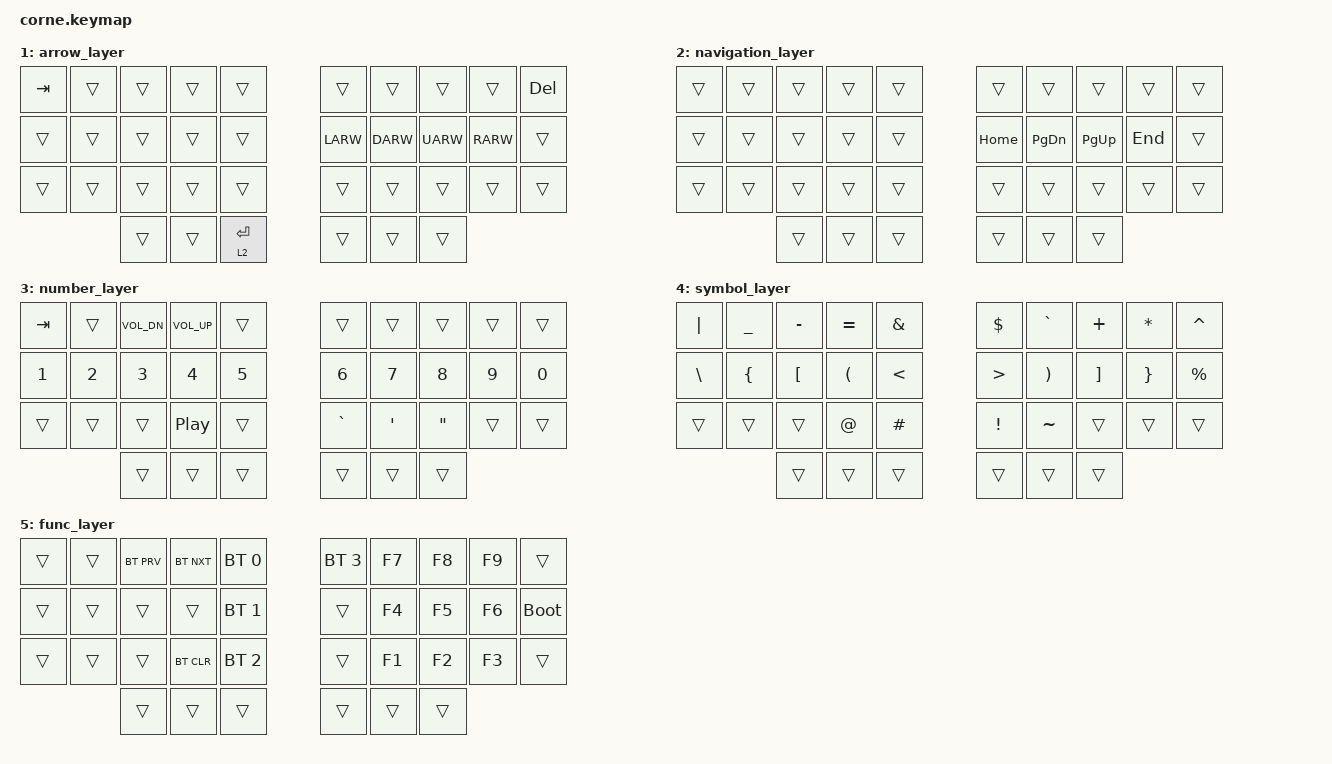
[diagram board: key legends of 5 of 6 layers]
/*
 * Copyright (c) 2021 The ZMK Contributors
 *
 * SPDX-License-Identifier: MIT
 */


#include <behaviors.dtsi>
#include <dt-bindings/zmk/keys.h>
#include <dt-bindings/zmk/bt.h>
#include <dt-bindings/zmk/outputs.h>

// Home row mods macro
#define HRML(k1,k2,k3,k4) &hm LSHFT k1  &hm LGUI k2  &hm LCTRL k3  &hm LALT k4
#define HRMR(k1,k2,k3,k4) &hm RALT k1  &hm RCTRL k2  &hm RGUI k3  &hm RSHFT k4

/ {
    behaviors {
        hm: hold_tap {
            compatible = "zmk,behavior-hold-tap";
            label = "HOMEROW_MODS";
            #binding-cells = <2>;
            tapping-term-ms = <175>;
            quick-tap-ms = <0>;
            flavor = "tap-preferred";
            bindings = <&kp>, <&kp>;
        };
    };


    behaviors {
        htl: hold_tap_layer {
            compatible = "zmk,behavior-hold-tap";
            label = "Thumb_CLUSTER";
            #binding-cells = <2>;
            tapping-term-ms = <250>;
            quick-tap-ms = <200>;
            flavor = "tap-preferred";
            bindings = <&mo>, <&kp>;
        };
    };

    conditional_layers {
        compatible = "zmk,conditional-layers";
        func_layer {
            if-layers = <1 3>;
            then-layer = <5>;
        };
    };

    keymap {
        compatible = "zmk,keymap";
        default_layer {
            bindings = <
        //╭──────────┬──────────┬──────────┬──────────┬──────────╮   ╭──────────┬──────────┬──────────┬──────────┬──────────╮
        //│  Q       │  W       │  E       │  R       │  T       │   │  Y       │  U       │  I       │  O       │  P       │
           &kp Q      &kp W      &kp E      &kp R      &kp T          &kp Y      &kp U      &kp I      &kp O      &kp P
        //├──────────┼──────────┼──────────┼──────────┼──────────┤   ├──────────┼──────────┼──────────┼──────────┼──────────┤
        //│  A       │  S       │  D       │  F       │  G       │   │  H       │  J       │  K       │  L       │ : ;      │
           HRML(A,        S,         D,         F)     &kp G          &kp H      HRMR(J,        K,         L,        SEMI)
        //├──────────┼──────────┼──────────┼──────────┼──────────┤   ├──────────┼──────────┼──────────┼──────────┼──────────┤
        //│  Z       │  X       │  C       │  V       │  B       │   │  N       │  M       │ , <      │ . >      │ / ?      │
           &kp Z      &kp X      &kp C      &kp V      &kp B          &kp N      &kp M      &kp COMMA  &kp DOT    &kp FSLH
        //╰──────────┴──────────┴──────────┼──────────┼──────────┤   ├──────────┼──────────┼──────────┴──────────┴──────────╯
                                &trans  &htl 3 ESC &htl 3 ENTER         &htl 4 SPACE &htl 1 BSPC &trans
        //                      ╰──────────┴──────────┴──────────╯   ╰──────────┴──────────┴──────────╯
            >;
        };

        arrow_layer {
            bindings = <
        //╭──────────┬──────────┬──────────┬──────────┬──────────╮   ╭──────────┬──────────┬──────────┬──────────┬──────────╮
        //│   TAB    │          │          │          │          │   │          │          │          │          │    DEL   │
           &kp TAB    &trans     &trans     &trans     &trans         &trans     &trans     &trans     &trans     &kp DEL
        //├──────────┼──────────┼──────────┼──────────┼──────────┤   ├──────────┼──────────┼──────────┼──────────┼──────────┤
        //│          │          │          │          │          │   │ LEFT     │ DOWN     │ UP       │ RIGhm    │          │
           &trans     &trans     &trans     &trans     &trans         &kp LARW   &kp DARW   &kp UARW   &kp RARW   &trans
        //├──────────┼──────────┼──────────┼──────────┼──────────┤   ├──────────┼──────────┼──────────┼──────────┼──────────┤
        //│          │          │          │          │          │   │          │          │          │          │          │
           &trans     &trans     &trans     &trans     &trans         &trans     &trans     &trans     &trans     &trans
        //╰──────────┴──────────┴──────────┼──────────┼──────────┤   ├──────────┼──────────┼──────────┴──────────┴──────────╯
                                          &trans   &trans     &htl 2 ENTER      &trans &trans &trans 
        //                                 ╰──────────┴──────────╯   ╰──────────┴──────────╯
            >;
        };

        navigation_layer {
            bindings = <
        //╭──────────┬──────────┬──────────┬──────────┬──────────╮   ╭──────────┬──────────┬──────────┬──────────┬──────────╮
        //│          │          │          │          │          │   │          │          │          │          │          │
           &trans     &trans     &trans     &trans     &trans         &trans     &trans     &trans     &trans     &trans  
        //├──────────┼──────────┼──────────┼──────────┼──────────┤   ├──────────┼──────────┼──────────┼──────────┼──────────┤
        //│          │          │          │          │          │   │          │          │          │          │          │
           &trans     &trans     &trans     &trans     &trans         &kp HOME   &kp PG_DN  &kp PG_UP  &kp END    &trans      
        //├──────────┼──────────┼──────────┼──────────┼──────────┤   ├──────────┼──────────┼──────────┼──────────┼──────────┤
        //│          │          │          │          │          │   │          │          │          │          │          │
           &trans     &trans     &trans     &trans     &trans         &trans     &trans     &trans     &trans     &trans
        //╰──────────┴──────────┴──────────┼──────────┼──────────┤   ├──────────┼──────────┼──────────┴──────────┴──────────╯
                                            &trans     &trans &trans         &trans     &trans &trans
        //                                 ╰──────────┴──────────╯   ╰──────────┴──────────╯
            >;
        };

        number_layer {
            bindings = <
        //╭──────────┬──────────┬──────────┬──────────┬──────────╮   ╭──────────┬──────────┬──────────┬──────────┬──────────╮
        //│   TAB    │          │ vol dwn  │  vol up  |          │   │          │          │          │          │          │
           &kp TAB    &trans  &kp C_VOL_DN &kp C_VOL_UP &trans        &trans     &trans     &trans     &trans     &trans  
        //├──────────┼──────────┼──────────┼──────────┼──────────┤   ├──────────┼──────────┼──────────┼──────────┼──────────┤
        //│          │          │          │          │          │   │          │          │          │          │          │
           &kp N1     &kp N2     &kp N3     &kp N4     &kp N5         &kp N6     &kp N7     &kp N8     &kp N9     &kp N0      
        //├──────────┼──────────┼──────────┼──────────┼──────────┤   ├──────────┼──────────┼──────────┼──────────┼──────────┤
        //│          │          │          |pause/play│          │   │    ` ~   │   ' "    │    "     │          │          │
           &trans     &trans     &trans     &kp C_PP   &trans         &kp GRAVE  &kp SQT    &kp DQT    &trans     &trans
        //╰──────────┴──────────┴──────────┼──────────┼──────────┤   ├──────────┼──────────┼──────────┴──────────┴──────────╯
                                            &trans     &trans &trans         &trans     &trans &trans
        //                                 ╰──────────┴──────────╯   ╰──────────┴──────────╯
            >;
        };

        symbol_layer {
            bindings = <
        //╭──────────┬──────────┬──────────┬──────────┬──────────╮   ╭──────────┬──────────┬──────────┬──────────┬──────────╮
        //│    |     │    _     │    -     │    =     │    &     │   │    $     │    `     │    +     │    *     │    ^     │
           &kp PIPE   &kp UNDER  &kp MINUS  &kp EQUAL  &kp AMPS       &kp DLLR   &kp GRAVE  &kp PLUS   &kp STAR   &kp CARET 
        //├──────────┼──────────┼──────────┼──────────┼──────────┤   ├──────────┼──────────┼──────────┼──────────┼──────────┤
        //│    \     │    {     │    [     │    (     │    <     │   │    >     │    )     │    ]     │    }     │    %     │
           &kp BSLH   &kp LBRC   &kp LBKT   &kp LPAR   &kp LT         &kp GT     &kp RPAR   &kp RBKT   &kp RBRC   &kp PRCNT      
        //├──────────┼──────────┼──────────┼──────────┼──────────┤   ├──────────┼──────────┼──────────┼──────────┼──────────┤
        //│          │          │          │    @     │    #     │   │    !     │    ~     │          │          │          │
           &trans     &trans     &trans     &kp AT     &kp HASH       &kp EXCL   &kp TILDE  &trans     &trans     &trans
        //╰──────────┴──────────┴──────────┼──────────┼──────────┤   ├──────────┼──────────┼──────────┴──────────┴──────────╯
                                             &trans     &trans &trans        &trans     &trans &trans
        //                                 ╰──────────┴──────────╯   ╰──────────┴──────────╯
            >;
        };

        func_layer {
            bindings = <
        //╭──────────┬──────────┬──────────┬──────────┬──────────╮   ╭──────────┬──────────┬──────────┬──────────┬──────────╮
        //│          │          │          │          │PROFILE 0 │   │PROFILE 3 │          │          │          │     │
           &trans     &trans     &bt BT_PRV &bt BT_NXT &bt BT_SEL 0   &bt BT_SEL 3 &kp F7   &kp F8     &kp F9     &trans
        //├──────────┼──────────┼──────────┼──────────┼──────────┤   ├──────────┼──────────┼──────────┼──────────┼──────────┤
        //│          │          │          │          │PROFILE 1 │   │          │          │          │          │BOOTLOADER│
           &trans     &trans     &trans     &trans     &bt BT_SEL 1   &trans     &kp F4     &kp F5     &kp F6     &bootloader
        //├──────────┼──────────┼──────────┼──────────┼──────────┤   ├──────────┼──────────┼──────────┼──────────┼──────────┤
        //│          │          │          │ CLEAR BT │PROFILE 2 │   │          │          │          │          │          │
           &trans     &trans     &trans     &bt BT_CLR &bt BT_SEL 2   &trans     &kp F1     &kp F2     &kp F3     &trans
        //╰──────────┴──────────┴──────────┼──────────┼──────────┤   ├──────────┼──────────┼──────────┴──────────┴──────────╯
                                            &trans     &trans &trans         &trans     &trans &trans
        //                                 ╰──────────┴──────────╯   ╰──────────┴──────────╯
            >;
        };
    };
};
